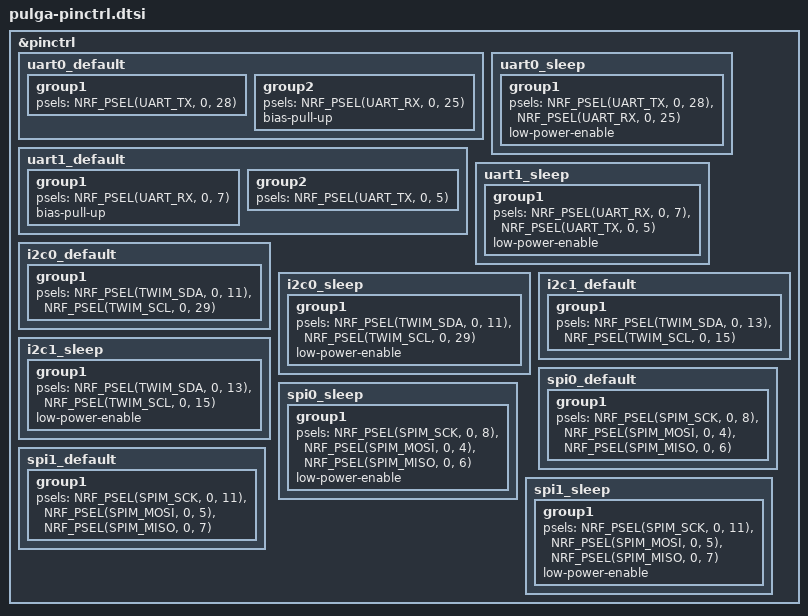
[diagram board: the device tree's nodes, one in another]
/*
 * Copyright (c) 2022 LSI-TEC
 * SPDX-License-Identifier: Apache-2.0
 */

&pinctrl { // TODO revise all these pins and the actual assignments
	uart0_default: uart0_default { // UART0 -- TX=P0.28 RX=P0.25
		group1 {
			psels = <NRF_PSEL(UART_TX, 0, 28)>;
		};
		group2 {
			psels = <NRF_PSEL(UART_RX, 0, 25)>;
			bias-pull-up;
		};
	};

	uart0_sleep: uart0_sleep {
		group1 {
			psels = <NRF_PSEL(UART_TX, 0, 28)>,
				<NRF_PSEL(UART_RX, 0, 25)>;
			low-power-enable;
		};
	};

	uart1_default: uart1_default { 
		group1 {
			psels = <NRF_PSEL(UART_RX, 0, 7)>;
			bias-pull-up;
		};
		group2 {
			psels = <NRF_PSEL(UART_TX, 0, 5)>;
		};
	};

	uart1_sleep: uart1_sleep {
		group1 {
			psels = <NRF_PSEL(UART_RX, 0, 7)>,
				<NRF_PSEL(UART_TX, 0, 5)>;
			low-power-enable;
		};
	};

	i2c0_default: i2c0_default {
		group1 {
			psels = <NRF_PSEL(TWIM_SDA, 0, 11)>,
				<NRF_PSEL(TWIM_SCL, 0, 29)>;
		};
	};

	i2c0_sleep: i2c0_sleep {
		group1 {
			psels = <NRF_PSEL(TWIM_SDA, 0, 11)>,
				<NRF_PSEL(TWIM_SCL, 0, 29)>;
			low-power-enable;
		};
	};

	i2c1_default: i2c1_default { // I2C1 -- SCL=P0.11 SDA=P0.29
		group1 {
			psels = <NRF_PSEL(TWIM_SDA, 0, 13)>,
				<NRF_PSEL(TWIM_SCL, 0, 15)>;
		};
	};

	i2c1_sleep: i2c1_sleep {
		group1 {
			psels = <NRF_PSEL(TWIM_SDA, 0, 13)>,
				<NRF_PSEL(TWIM_SCL, 0, 15)>;
			low-power-enable;
		};
	};
/*
	pwm0_default: pwm0_default { // TODO where is the PWM?
		group1 {
			psels = <NRF_PSEL(PWM_OUT0, 0, 13)>;
			nordic,invert;
		};
	};

	pwm0_sleep: pwm0_sleep {
		group1 {
			psels = <NRF_PSEL(PWM_OUT0, 0, 13)>;
			low-power-enable;
		};
	};
*/
	spi0_default: spi0_default {
		group1 {
			psels = <NRF_PSEL(SPIM_SCK, 0, 8)>,
				<NRF_PSEL(SPIM_MOSI, 0, 4)>,
				<NRF_PSEL(SPIM_MISO, 0, 6)>;
		};
	};

	spi0_sleep: spi0_sleep {
		group1 {
			psels = <NRF_PSEL(SPIM_SCK, 0, 8)>,
				<NRF_PSEL(SPIM_MOSI, 0, 4)>,
				<NRF_PSEL(SPIM_MISO, 0, 6)>;
			low-power-enable;
		};
	};

	spi1_default: spi1_default {
		group1 {
			psels = <NRF_PSEL(SPIM_SCK, 0, 11)>,
				<NRF_PSEL(SPIM_MOSI, 0, 5)>,
				<NRF_PSEL(SPIM_MISO, 0, 7)>;
		};
	};

	spi1_sleep: spi1_sleep {
		group1 {
			psels = <NRF_PSEL(SPIM_SCK, 0, 11)>,
				<NRF_PSEL(SPIM_MOSI, 0, 5)>,
				<NRF_PSEL(SPIM_MISO, 0, 7)>;
			low-power-enable;
		};
	};
};
